VERSION ""

NS_ :

BS_:

BU_: CCS_Controller BMS DCDC OBCharger
VAL_TABLE_ V2G_Mode 6 "Reserved" 5 "Reserved" 4 "Reserved" 3 "V2V Enable" 2 "V2L Enable" 1 "V2G Enable" 0 "Off" ;
VAL_TABLE_ DCDC_Warm_Temp 1 "Temp Warn" 0 "Normal Temp" ;
VAL_TABLE_ DCDC_OverVoltage_output 1 "Error" 0 "No Error" ;
VAL_TABLE_ DCDC_OverVoltage_Input 1 "Error" 0 "No Error" ;
VAL_TABLE_ DCDC_Over_Temp 1 "Error" 0 "No Error" ;
VAL_TABLE_ DCDC_LowVoltage_ouptut 1 "Error" 0 "No Error" ;
VAL_TABLE_ DCDC_LowVoltage_input 1 "Error" 0 "No Error" ;
VAL_TABLE_ DCDC_OverCurr_output 1 "Error" 0 "No Error" ;
VAL_TABLE_ DCDC_Ready 1 "Init Complete" 0 "Init Not Complete" ;
VAL_TABLE_ DCDC_Status 1 "Working" 0 "Not Working" ;
VAL_TABLE_ DCDC_Hard_Fault 1 "Error" 0 "No Error" ;
VAL_TABLE_ DCDC_CAN_error 1 "Error" 0 "No Error" ;
VAL_TABLE_ DCDC_Stop_ERR 1 "Error" 0 "No Error" ;
VAL_TABLE_ DCDC_Fan_control 1 "Fan On" 0 "Fan Off" ;
VAL_TABLE_ DCDC_Water_Fan 1 "Fan On" 0 "Fan Off" ;
VAL_TABLE_ Charger1Communication_State 1 "Yes" 0 "No" ;
VAL_TABLE_ Charger1Starting 1 "Error HV Battery Not Detected" 0 "Charger Detected Battery" ;
VAL_TABLE_ Charger1InVoltageFault 1 "Input Voltage Error" 0 "Input Voltage Normal" ;
VAL_TABLE_ Charger1OverTemp 1 "Over Temp Protection" 0 "Normal" ;
VAL_TABLE_ Charger1HarwareFailure 1 "Hardware Failure" 0 "Normal" ;
VAL_TABLE_ Charge_Control_Signal 1 "Stop Charging" 0 "Start Charging" ;
VAL_TABLE_ DCDC_Control_Command 2 "Stop" 1 "Start" ;
VAL_TABLE_ NO_Yes 1 "Yes" 0 "No" ;

BO_ 3221225472 VECTOR__INDEPENDENT_SIG_MSG: 0 Vector__XXX
 SG_ Contactor_Closure_Request : 0|1@1+ (1,0) [0|0] "" Vector__XXX
 SG_ LV12VBatVoltage : 0|16@1+ (0.1,0) [0|6553.5] "V" Vector__XXX
 SG_ DCDC_Protect_Command : 0|2@0+ (1,0) [0|3] "" Vector__XXX

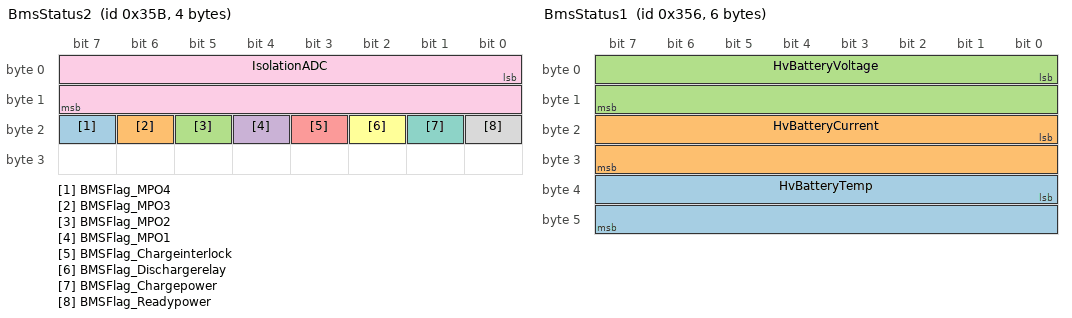
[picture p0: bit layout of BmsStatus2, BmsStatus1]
BO_ 859 BmsStatus2: 4 BMS
 SG_ BMSFlag_MPO4 : 23|1@1+ (1,0) [0|1] "" Vector__XXX
 SG_ BMSFlag_MPO3 : 22|1@1+ (1,0) [0|1] "" Vector__XXX
 SG_ BMSFlag_MPO2 : 21|1@1+ (1,0) [0|1] "" Vector__XXX
 SG_ BMSFlag_MPO1 : 20|1@1+ (1,0) [0|1] "" Vector__XXX
 SG_ BMSFlag_Chargeinterlock : 19|1@1+ (1,0) [0|1] "" Vector__XXX
 SG_ BMSFlag_Dischargerelay : 18|1@1+ (1,0) [0|1] "" Vector__XXX
 SG_ BMSFlag_Chargepower : 17|1@1+ (1,0) [0|1] "" Vector__XXX
 SG_ BMSFlag_Readypower : 16|1@1+ (1,0) [0|1] "" Vector__XXX
 SG_ IsolationADC : 0|16@1+ (0.001,0) [0|0] "v" Vector__XXX

BO_ 874 CCSStatus: 8 CCS_Controller
 SG_ CCSDisabled : 48|1@1- (1,0) [0|0] "" Vector__XXX
 SG_ BatteryVoltageSense : 23|16@0+ (0.1,0) [0|6553.5] "v"  BMS
 SG_ CCSVoltageSense : 39|16@0+ (0.1,0) [0|6553.5] "v"  BMS
 SG_ StopchargeSwitch : 15|1@1+ (1,0) [0|0] ""  BMS
 SG_ InletFault : 14|1@1+ (1,0) [0|1] ""  BMS
 SG_ HVPresent : 13|1@1+ (1,0) [0|1] ""  BMS
 SG_ CCSContactorStatus : 12|1@1+ (1,0) [0|1] ""  BMS
 SG_ InletMotor : 11|1@1+ (1,0) [0|1] ""  BMS
 SG_ PlugPresent : 10|1@1+ (1,0) [0|1] ""  BMS
 SG_ ChargeMode : 9|1@1+ (1,0) [0|1] ""  BMS
 SG_ IncompatibleCCSCharger : 8|1@1+ (1,0) [0|1] ""  BMS
 SG_ ChargeProtocolFault : 7|1@1+ (1,0) [0|1] ""  BMS
 SG_ PTCTempFault : 6|1@1+ (1,0) [0|1] ""  BMS
 SG_ CCSECUFault : 5|1@1+ (1,0) [0|1] ""  BMS
 SG_ BMSFault : 4|1@1+ (1,0) [0|1] ""  BMS
 SG_ BMSCommsFault : 3|1@1+ (1,0) [0|1] ""  BMS
 SG_ HVILFault : 2|1@1+ (1,0) [0|1] ""  BMS
 SG_ CCSContactorFault : 1|1@1+ (1,0) [0|1] ""  BMS
 SG_ HVPreChargeFault : 0|1@1+ (1,0) [0|1] ""  BMS

BO_ 855 BMSCCSCommands: 3 CCS_Controller
 SG_ ACCurrentLimit : 8|16@1+ (1,0) [0|65535] ""  BMS
 SG_ IsolationRelayOverride : 0|1@1+ (1,0) [0|1] ""  BMS

BO_ 858 BmsErrors: 4 BMS
 SG_ P0A06_ChgLimitEnforceFault : 31|1@1+ (1,0) [0|1] ""  CCS_Controller
 SG_ P0A05_InputPSUFault : 30|1@1+ (1,0) [0|1] ""  CCS_Controller
 SG_ P0AA6_HVIsolationFault : 29|1@1+ (1,0) [0|1] ""  CCS_Controller
 SG_ P0560_RedundantPSUFault : 28|1@1+ (1,0) [0|1] ""  CCS_Controller
 SG_ U0100_ExternalComms : 27|1@1+ (1,0) [0|1] ""  CCS_Controller
 SG_ P0A9C_ThermistorFault : 26|1@1+ (1,0) [0|1] ""  CCS_Controller
 SG_ P0A81_FanMornitorFault : 25|1@1+ (1,0) [0|1] ""  CCS_Controller
 SG_ P0A02_WeakPackFault : 24|1@1+ (1,0) [0|1] ""  CCS_Controller
 SG_ P0A0F_CellASICFault : 23|1@1+ (1,0) [0|1] ""  CCS_Controller
 SG_ P0A0D_HighCell5VFault : 22|1@1+ (1,0) [0|1] ""  CCS_Controller
 SG_ P0AC0_CurrentSensorFault : 21|1@1+ (1,0) [0|1] ""  CCS_Controller
 SG_ P0A04_OpenWiringFault : 20|1@1+ (1,0) [0|1] ""  CCS_Controller
 SG_ P0AFA_LowCellVoltFault : 19|1@1+ (1,0) [0|1] ""  CCS_Controller
 SG_ P0A80_WeakCellFault : 18|1@1+ (1,0) [0|1] ""  CCS_Controller
 SG_ P0A12_CellBallanceOffFault : 17|1@1+ (1,0) [0|1] ""  CCS_Controller
 SG_ P0A1F_InternalCommsFault : 16|1@1+ (1,0) [0|1] ""  CCS_Controller
 SG_ P0A10_PackHotFault : 7|1@1+ (1,0) [0|1] ""  CCS_Controller
 SG_ P0A0E_LowCellFault : 6|1@1+ (1,0) [0|1] ""  CCS_Controller
 SG_ P0A0C_HighCellFault : 5|1@1+ (1,0) [0|1] ""  CCS_Controller
 SG_ P0A0B_IntSWFault : 4|1@1+ (1,0) [0|1] ""  CCS_Controller
 SG_ P0A0A_IntHeatsinkFault : 3|1@1+ (1,0) [0|1] ""  CCS_Controller
 SG_ P0A09_InternalHWFault : 2|1@1+ (1,0) [0|1] ""  CCS_Controller
 SG_ P0A08_ChgSafetyRelay : 1|1@1+ (1,0) [0|1] ""  CCS_Controller
 SG_ P0A07_DischgLimitEnforceFault : 0|1@1+ (1,0) [0|1] ""  CCS_Controller

BO_ 854 BmsStatus1: 6 BMS
 SG_ HvBatteryTemp : 32|16@1- (0.1,0) [-3276.8|3276.7] "C"  CCS_Controller
 SG_ HvBatteryCurrent : 16|16@1- (0.1,0) [-3276.8|3276.7] "A"  CCS_Controller
 SG_ HvBatteryVoltage : 0|16@1+ (0.1,0) [0|655.35] "V"  CCS_Controller

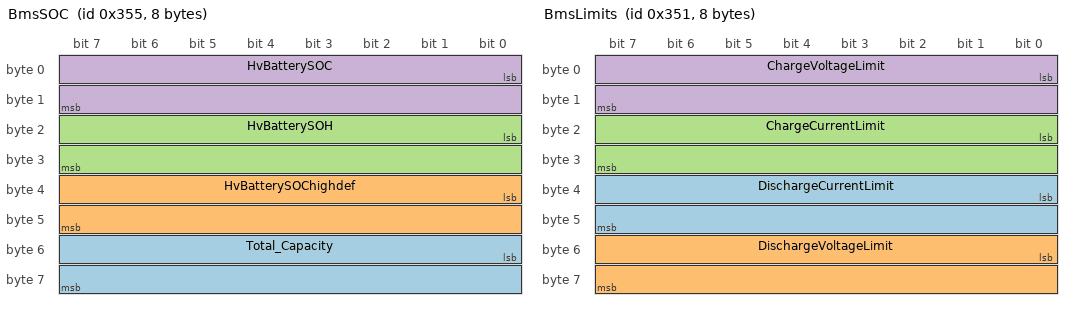
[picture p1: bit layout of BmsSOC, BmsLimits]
BO_ 853 BmsSOC: 8 BMS
 SG_ Total_Capacity : 48|16@1+ (0.1,0) [0|0] "Ah" Vector__XXX
 SG_ HvBatterySOChighdef : 32|16@1+ (0.1,0) [0|655.35] "%" Vector__XXX
 SG_ HvBatterySOH : 16|16@1+ (1,0) [0|65535] "%" Vector__XXX
 SG_ HvBatterySOC : 0|16@1+ (1,0) [0|65535] "%"  CCS_Controller

BO_ 849 BmsLimits: 8 BMS
 SG_ DischargeCurrentLimit : 32|16@1+ (0.1,0) [0|65535] "A"  CCS_Controller
 SG_ DischargeVoltageLimit : 48|16@1+ (0.1,0) [0|6553.5] "V"  CCS_Controller
 SG_ ChargeCurrentLimit : 16|16@1+ (0.1,0) [0|6553.5] "A"  CCS_Controller
 SG_ ChargeVoltageLimit : 0|16@1+ (0.1,0) [0|6553.5] "V"  CCS_Controller

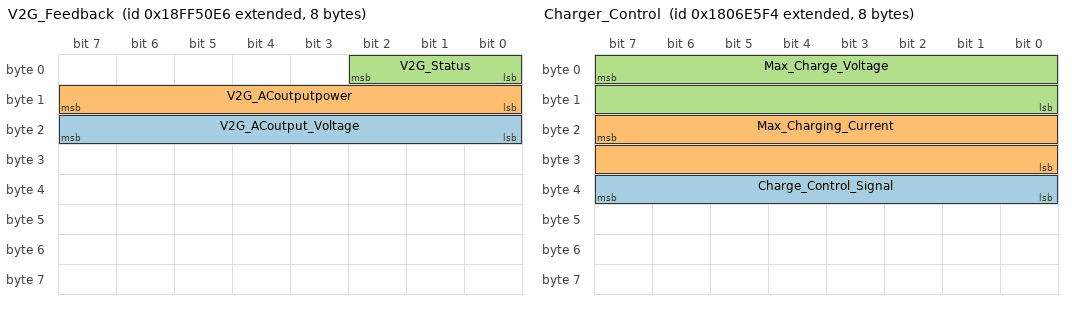
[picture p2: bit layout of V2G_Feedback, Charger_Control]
BO_ 2566869222 V2G_Feedback: 8 OBCharger
 SG_ V2G_ACoutput_Voltage : 23|8@0+ (1,0) [0|255] "V" Vector__XXX
 SG_ V2G_ACoutputpower : 15|8@0+ (0.1,0) [0|25.5] "kw" Vector__XXX
 SG_ V2G_Status : 2|3@0+ (1,0) [0|7] "" Vector__XXX

BO_ 2550588917 V2G_Control: 8 Vector__XXX
 SG_ V2G_Mode : 7|3@0+ (1,0) [0|7] "" Vector__XXX

BO_ 2550173648 DCDC_Control: 8 Vector__XXX
 SG_ DCDC_Control_Command : 1|2@0+ (1,0) [0|3] ""  DCDC

BO_ 2550255759 DCDC_Feedback: 8 DCDC
 SG_ DCDC_Temperature : 63|8@0+ (0.1,0) [0|255] "C" Vector__XXX
 SG_ DCDC_Warm_Temp : 40|1@0+ (1,0) [0|1] "" Vector__XXX
 SG_ DCDC_OverVoltage_output : 44|1@0+ (1,0) [0|0] "" Vector__XXX
 SG_ DCDC_OverVoltage_Input : 42|1@0+ (1,0) [0|1] "" Vector__XXX
 SG_ DCDC_Over_Temp : 41|1@0+ (1,0) [0|1] "" Vector__XXX
 SG_ DCDC_LowVoltage_ouptut : 45|1@0+ (1,0) [0|1] "" Vector__XXX
 SG_ DCDC_LowVoltage_input : 43|1@0+ (1,0) [0|1] "" Vector__XXX
 SG_ DCDC_OverCurr_output : 46|1@0+ (1,0) [0|1] "" Vector__XXX
 SG_ DCDC_Ready : 32|1@0+ (1,0) [0|1] "" Vector__XXX
 SG_ DCDC_Status : 33|1@0+ (1,0) [0|1] "" Vector__XXX
 SG_ DCDC_Hard_Fault : 34|1@0+ (1,0) [0|1] "" Vector__XXX
 SG_ DCDC_CAN_error : 35|1@0+ (1,0) [0|255] "" Vector__XXX
 SG_ DCDC_Stop_ERR : 37|1@0+ (1,0) [0|1] "" Vector__XXX
 SG_ DCDC_Fan_control : 36|1@0+ (1,0) [0|1] "" Vector__XXX
 SG_ DCDC_Water_Fan : 38|1@0+ (1,0) [0|1] "" Vector__XXX
 SG_ DCDC_HVIL_ERR : 39|1@0+ (1,0) [0|1] "" Vector__XXX
 SG_ DCDC_Current : 23|16@0+ (0.1,0) [0|65535] "A" Vector__XXX
 SG_ DCDC_Voltage_12V : 7|16@0+ (0.1,0) [0|6553.5] "V" Vector__XXX

BO_ 2550588916 Charger_Control: 8 Vector__XXX
 SG_ Charge_Control_Signal : 39|8@0+ (1,0) [0|0] ""  OBCharger
 SG_ Max_Charging_Current : 23|16@0+ (0.1,0) [0|22.93725] "A"  OBCharger
 SG_ Max_Charge_Voltage : 7|16@0+ (0.1,0) [0|6553.5] "V"  OBCharger

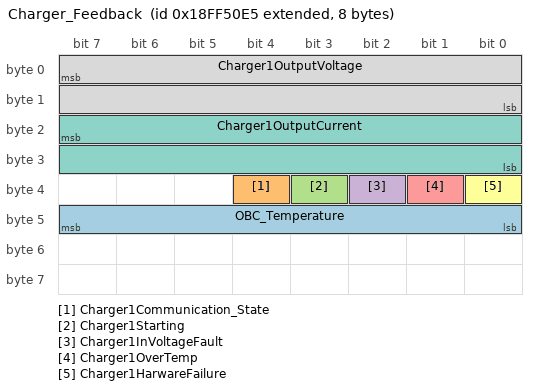
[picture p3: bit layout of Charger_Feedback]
BO_ 2566869221 Charger_Feedback: 8 OBCharger
 SG_ OBC_Temperature : 47|8@0+ (1,0) [0|255] "C" Vector__XXX
 SG_ Charger1Communication_State : 36|1@0+ (1,0) [0|1] "" Vector__XXX
 SG_ Charger1Starting : 35|1@0+ (1,0) [0|1] "" Vector__XXX
 SG_ Charger1InVoltageFault : 34|1@0+ (1,0) [0|1] "" Vector__XXX
 SG_ Charger1OverTemp : 33|1@0+ (1,0) [0|1] "" Vector__XXX
 SG_ Charger1HarwareFailure : 32|1@0+ (1,0) [0|1] "" Vector__XXX
 SG_ Charger1OutputCurrent : 23|16@0+ (0.1,0) [0|65.535] "A" Vector__XXX
 SG_ Charger1OutputVoltage : 7|16@0+ (0.1,0) [0|65.535] "V" Vector__XXX

CM_ BO_ 3221225472 "This is a message for not used signals, created by Vector CANdb++ DBC OLE DB Provider.";
CM_ SG_ 874 InletFault "0 = OK
1 = Fault";
CM_ SG_ 874 HVPresent "1 = Precharge ok, hv present
0 = No HV Present";
CM_ SG_ 874 InletMotor "0 = Unlocked
1 = Locked";
CM_ SG_ 874 PlugPresent "0 = No Plug Present
1 = Plug Present";
CM_ SG_ 874 ChargeMode "0 = AC Charging
1 = DC Fastcharge";
CM_ SG_ 855 IsolationRelayOverride "0=BMS Isolation monitoring on
1=BMS Isolation monitoring off";
CM_ SG_ 854 HvBatteryCurrent "Negative current for charging";
BA_DEF_ SG_  "GenSigSendType" ENUM  "Cyclic","OnWrite","OnWriteWithRepetition","OnChange","OnChangeWithRepetition","IfActive","IfActiveWithRepetition","NoSigSendType";
BA_DEF_ SG_  "GenSigILSupport" ENUM  "No","Yes";
BA_DEF_ SG_  "GenSigEVName" STRING ;
BA_DEF_ SG_  "SigType" ENUM  "Default","Range","RangeSigned","ASCII","Discrete","Control","ReferencePGN","DTC","StringDelimiter","StringLength","StringLengthControl";
BA_DEF_ BO_  "VFrameFormat" ENUM  "StandardCAN","ExtendedCAN","reserved","J1939PG";
BA_DEF_ BO_  "GenMsgCycleTime" INT 0 3600000;
BA_DEF_ BO_  "GenMsgRequestable" INT 0 1;
BA_DEF_ BO_  "GenMsgSendType" ENUM  "cyclic","NotUsed","IfActive","NotUsed","NotUsed","NotUsed","NotUsed","NotUsed","noMsgSendType";
BA_DEF_ BO_  "GenMsgILSupport" ENUM  "No","Yes";
BA_DEF_ BU_  "NmStationAddress" INT 0 255;
BA_DEF_ BU_  "NodeLayerModules" STRING ;
BA_DEF_ BU_  "NmAsrCanMsgReducedTime" INT 0 65535;
BA_DEF_ BU_  "NmAsrNode" ENUM  "no","yes";
BA_DEF_  "ProtocolType" STRING ;
BA_DEF_  "DBName" STRING ;
BA_DEF_  "NmAsrBaseAddress" HEX 0 536870911;
BA_DEF_  "NmAsrCanMsgCycleTime" INT 0 65535;
BA_DEF_  "NmAsrMessageCount" INT 0 256;
BA_DEF_  "NmAsrRepeatMessageTime" INT 0 65535;
BA_DEF_  "NmAsrTimeoutTime" INT 0 65535;
BA_DEF_  "NmAsrWaitBusSleepTime" INT 0 65535;
BA_DEF_  "Baudrate" INT 0 10000000;
BA_DEF_  "BusType" STRING ;
BA_DEF_DEF_  "GenSigSendType" "NoSigSendType";
BA_DEF_DEF_  "GenSigILSupport" "Yes";
BA_DEF_DEF_  "GenSigEVName" "Env@Nodename_@Signame";
BA_DEF_DEF_  "SigType" "Default";
BA_DEF_DEF_  "VFrameFormat" "J1939PG";
BA_DEF_DEF_  "GenMsgCycleTime" 0;
BA_DEF_DEF_  "GenMsgRequestable" 1;
BA_DEF_DEF_  "GenMsgSendType" "noMsgSendType";
BA_DEF_DEF_  "GenMsgILSupport" "Yes";
BA_DEF_DEF_  "NmStationAddress" 254;
BA_DEF_DEF_  "NodeLayerModules" "J1939_IL.dll";
BA_DEF_DEF_  "NmAsrCanMsgReducedTime" 50;
BA_DEF_DEF_  "NmAsrNode" "yes";
BA_DEF_DEF_  "ProtocolType" "J1939";
BA_DEF_DEF_  "DBName" "";
BA_DEF_DEF_  "NmAsrBaseAddress" 486506496;
BA_DEF_DEF_  "NmAsrCanMsgCycleTime" 100;
BA_DEF_DEF_  "NmAsrMessageCount" 64;
BA_DEF_DEF_  "NmAsrRepeatMessageTime" 400;
BA_DEF_DEF_  "NmAsrTimeoutTime" 1000;
BA_DEF_DEF_  "NmAsrWaitBusSleepTime" 750;
BA_DEF_DEF_  "Baudrate" 500000;
BA_DEF_DEF_  "BusType" "CAN";
BA_ "ProtocolType" "CAN";
BA_ "DBName" "ZeroEv";
BA_ "NmStationAddress" BU_ CCS_Controller 2;
BA_ "NmStationAddress" BU_ BMS 1;
BA_ "NmStationAddress" BU_ DCDC 3;
BA_ "NmStationAddress" BU_ OBCharger 4;
BA_ "VFrameFormat" BO_ 859 0;
BA_ "GenMsgCycleTime" BO_ 859 500;
BA_ "GenMsgSendType" BO_ 859 0;
BA_ "GenMsgSendType" BO_ 874 0;
BA_ "GenMsgCycleTime" BO_ 874 500;
BA_ "VFrameFormat" BO_ 874 0;
BA_ "GenMsgSendType" BO_ 855 0;
BA_ "GenMsgCycleTime" BO_ 855 200;
BA_ "VFrameFormat" BO_ 855 0;
BA_ "GenMsgSendType" BO_ 858 0;
BA_ "GenMsgCycleTime" BO_ 858 500;
BA_ "VFrameFormat" BO_ 858 0;
BA_ "GenMsgSendType" BO_ 854 0;
BA_ "GenMsgCycleTime" BO_ 854 100;
BA_ "VFrameFormat" BO_ 854 0;
BA_ "GenMsgSendType" BO_ 853 0;
BA_ "GenMsgCycleTime" BO_ 853 100;
BA_ "VFrameFormat" BO_ 853 0;
BA_ "GenMsgSendType" BO_ 849 0;
BA_ "GenMsgCycleTime" BO_ 849 100;
BA_ "VFrameFormat" BO_ 849 0;
VAL_ 3221225472 Contactor_Closure_Request 1 "Yes" 0 "No" ;
VAL_ 874 StopchargeSwitch 1 "Pressed" 0 "Not pressed" ;
VAL_ 874 InletFault 1 "Yes" 0 "No" ;
VAL_ 874 HVPresent 1 "HV Online" 0 "No" ;
VAL_ 874 CCSContactorStatus 1 "Closed" 0 "Open" ;
VAL_ 874 InletMotor 1 "Locked" 0 "Unlocked" ;
VAL_ 874 PlugPresent 1 "Plug detected" 0 "No plug" ;
VAL_ 874 ChargeMode 1 "DC" 0 "AC" ;
VAL_ 874 IncompatibleCCSCharger 1 "Yes" 0 "No" ;
VAL_ 874 ChargeProtocolFault 1 "Yes" 0 "No" ;
VAL_ 874 PTCTempFault 1 "Yes" 0 "No" ;
VAL_ 874 CCSECUFault 1 "Yes" 0 "No" ;
VAL_ 874 BMSFault 1 "Yes" 0 "No" ;
VAL_ 874 BMSCommsFault 1 "Yes" 0 "No" ;
VAL_ 874 HVILFault 1 "Yes" 0 "No" ;
VAL_ 874 CCSContactorFault 1 "Yes" 0 "No" ;
VAL_ 874 HVPreChargeFault 1 "Yes" 0 "No" ;
VAL_ 2566869222 V2G_Status 6 "Reserved" 5 "Reserved" 4 "Reserved" 3 "V2V Enable" 2 "V2L Enable" 1 "V2G Enable" 0 "Off" ;
VAL_ 2550588917 V2G_Mode 6 "Reserved" 5 "Reserved" 4 "Reserved" 3 "V2V Enable" 2 "V2L Enable" 1 "V2G Enable" 0 "Off" ;
VAL_ 2550173648 DCDC_Control_Command 2 "Stop" 1 "Start" ;
VAL_ 2550255759 DCDC_Warm_Temp 1 "Temp Warn" 0 "Normal Temp" ;
VAL_ 2550255759 DCDC_OverVoltage_output 1 "Error" 0 "No Error" ;
VAL_ 2550255759 DCDC_OverVoltage_Input 1 "Error" 0 "No Error" ;
VAL_ 2550255759 DCDC_Over_Temp 1 "Error" 0 "No Error" ;
VAL_ 2550255759 DCDC_LowVoltage_ouptut 1 "Error" 0 "No Error" ;
VAL_ 2550255759 DCDC_LowVoltage_input 1 "Error" 0 "No Error" ;
VAL_ 2550255759 DCDC_OverCurr_output 1 "Error" 0 "No Error" ;
VAL_ 2550255759 DCDC_Ready 1 "Init Complete" 0 "Init Not Complete" ;
VAL_ 2550255759 DCDC_Status 1 "Working" 0 "Not Working" ;
VAL_ 2550255759 DCDC_Hard_Fault 1 "Error" 0 "No Error" ;
VAL_ 2550255759 DCDC_CAN_error 1 "Error" 0 "No Error" ;
VAL_ 2550255759 DCDC_Stop_ERR 1 "Error" 0 "No Error" ;
VAL_ 2550255759 DCDC_Fan_control 1 "Fan On" 0 "Fan Off" ;
VAL_ 2550255759 DCDC_Water_Fan 1 "Fan On" 0 "Fan Off" ;
VAL_ 2550588916 Charge_Control_Signal 1 "Stop Charging" 0 "Start Charging" ;
VAL_ 2566869221 Charger1Communication_State 1 "Yes" 0 "No" ;
VAL_ 2566869221 Charger1Starting 1 "Error HV Battery Not Detected" 0 "Charger Detected Battery" ;
VAL_ 2566869221 Charger1InVoltageFault 1 "Input Voltage Error" 0 "Input Voltage Normal" ;
VAL_ 2566869221 Charger1OverTemp 1 "Over Temp Protection" 0 "Normal" ;
VAL_ 2566869221 Charger1HarwareFailure 1 "Hardware Failure" 0 "Normal" ;
